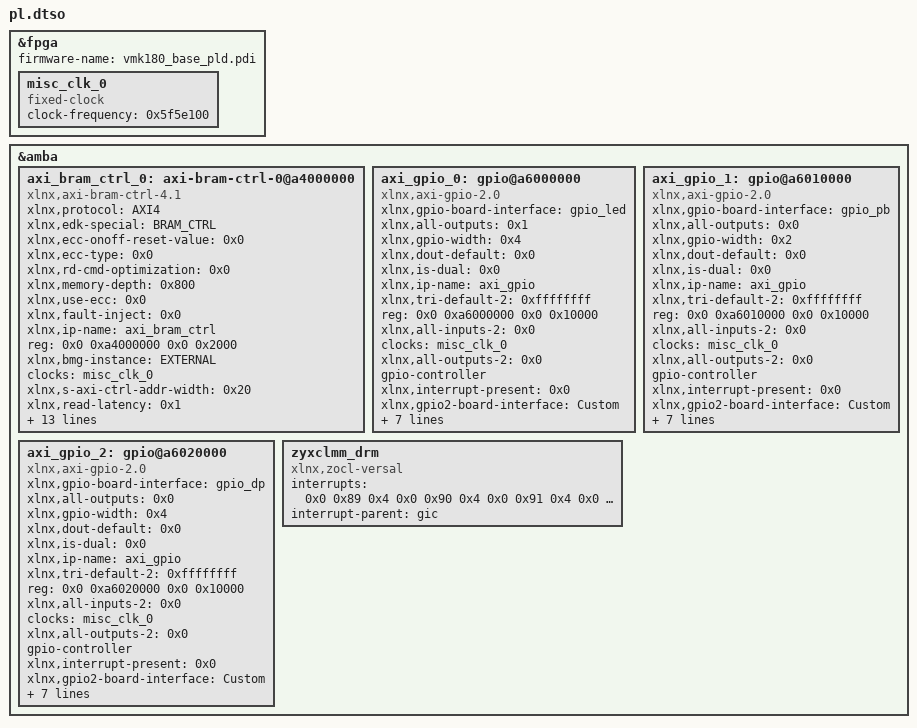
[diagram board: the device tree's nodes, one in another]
/dts-v1/;
/plugin/;

&fpga {
        firmware-name = "vmk180_base_pld.pdi";

        misc_clk_0: misc_clk_0 {
                compatible = "fixed-clock";
                clock-frequency = <0x5f5e100>;
                #clock-cells = <0x0>;
        };
};

&amba {

        axi_bram_ctrl_0: axi-bram-ctrl-0@a4000000 {
                xlnx,protocol = "AXI4";
                xlnx,edk-special = "BRAM_CTRL";
                compatible = "xlnx,axi-bram-ctrl-4.1", "xlnx,axi-bram-ctrl";
                xlnx,ecc-onoff-reset-value = <0x0>;
                xlnx,ecc-type = <0x0>;
                xlnx,rd-cmd-optimization = <0x0>;
                xlnx,memory-depth = <0x800>;
                xlnx,use-ecc = <0x0>;
                xlnx,fault-inject = <0x0>;
                xlnx,ip-name = "axi_bram_ctrl";
                reg = <0x0 0xa4000000 0x0 0x2000>;
                xlnx,bmg-instance = "EXTERNAL";
                clocks = <&misc_clk_0>;
                xlnx,s-axi-ctrl-addr-width = <0x20>;
                xlnx,read-latency = <0x1>;
                xlnx,id-width = <0x0>;
                xlnx,s-axi-supports-narrow-burst = <0x0>;
                xlnx,supports-narrow-burst = <0x0>;
                xlnx,single-port-bram = <0x0>;
                xlnx,ecc = <0x0>;
                xlnx,edk-iptype = "PERIPHERAL";
                clock-names = "s_axi_aclk";
                xlnx,data-width = <0x20>;
                xlnx,bram-addr-width = <0xb>;
                xlnx,bram-inst-mode = "EXTERNAL";
                xlnx,s-axi-ctrl-data-width = <0x20>;
                xlnx,mem-depth = <0x800>;
                xlnx,s-axi-id-width = <0x1>;
                xlnx,name = "axi_bram_ctrl_0";
        };

        axi_gpio_0: gpio@a6000000 {
                xlnx,gpio-board-interface = "gpio_led";
                compatible = "xlnx,axi-gpio-2.0", "xlnx,xps-gpio-1.00.a";
                xlnx,all-outputs = <0x1>;
                #gpio-cells = <0x2>;
                xlnx,gpio-width = <0x4>;
                xlnx,dout-default = <0x0>;
                xlnx,is-dual = <0x0>;
                xlnx,ip-name = "axi_gpio";
                xlnx,tri-default-2 = <0xffffffff>;
                reg = <0x0 0xa6000000 0x0 0x10000>;
                xlnx,all-inputs-2 = <0x0>;
                clocks = <&misc_clk_0>;
                xlnx,all-outputs-2 = <0x0>;
                gpio-controller;
                device_type = "gpio";
                xlnx,interrupt-present = <0x0>;
                xlnx,gpio2-board-interface = "Custom";
                xlnx,edk-iptype = "PERIPHERAL";
                xlnx,dout-default-2 = <0x0>;
                xlnx,gpio2-width = <0x20>;
                clock-names = "s_axi_aclk";
                xlnx,use-board-flow;
                xlnx,tri-default = <0xffffffff>;
                xlnx,name = "axi_gpio_0";
                xlnx,all-inputs = <0x0>;
        };

        axi_gpio_1: gpio@a6010000 {
                xlnx,gpio-board-interface = "gpio_pb";
                compatible = "xlnx,axi-gpio-2.0", "xlnx,xps-gpio-1.00.a";
                xlnx,all-outputs = <0x0>;
                #gpio-cells = <0x2>;
                xlnx,gpio-width = <0x2>;
                xlnx,dout-default = <0x0>;
                xlnx,is-dual = <0x0>;
                xlnx,ip-name = "axi_gpio";
                xlnx,tri-default-2 = <0xffffffff>;
                reg = <0x0 0xa6010000 0x0 0x10000>;
                xlnx,all-inputs-2 = <0x0>;
                clocks = <&misc_clk_0>;
                xlnx,all-outputs-2 = <0x0>;
                gpio-controller;
                device_type = "gpio";
                xlnx,interrupt-present = <0x0>;
                xlnx,gpio2-board-interface = "Custom";
                xlnx,edk-iptype = "PERIPHERAL";
                xlnx,dout-default-2 = <0x0>;
                xlnx,gpio2-width = <0x20>;
                clock-names = "s_axi_aclk";
                xlnx,use-board-flow;
                xlnx,tri-default = <0xffffffff>;
                xlnx,name = "axi_gpio_1";
                xlnx,all-inputs = <0x1>;
        };

        axi_gpio_2: gpio@a6020000 {
                xlnx,gpio-board-interface = "gpio_dp";
                compatible = "xlnx,axi-gpio-2.0", "xlnx,xps-gpio-1.00.a";
                xlnx,all-outputs = <0x0>;
                #gpio-cells = <0x2>;
                xlnx,gpio-width = <0x4>;
                xlnx,dout-default = <0x0>;
                xlnx,is-dual = <0x0>;
                xlnx,ip-name = "axi_gpio";
                xlnx,tri-default-2 = <0xffffffff>;
                reg = <0x0 0xa6020000 0x0 0x10000>;
                xlnx,all-inputs-2 = <0x0>;
                clocks = <&misc_clk_0>;
                xlnx,all-outputs-2 = <0x0>;
                gpio-controller;
                device_type = "gpio";
                xlnx,interrupt-present = <0x0>;
                xlnx,gpio2-board-interface = "Custom";
                xlnx,edk-iptype = "PERIPHERAL";
                xlnx,dout-default-2 = <0x0>;
                xlnx,gpio2-width = <0x20>;
                clock-names = "s_axi_aclk";
                xlnx,use-board-flow;
                xlnx,tri-default = <0xffffffff>;
                xlnx,name = "axi_gpio_2";
                xlnx,all-inputs = <0x1>;
        };

        zyxclmm_drm {
                interrupts = <0x0 0x89 0x4 0x0 0x90 0x4 0x0 0x91 0x4 0x0 0x92 0x4 0x0 0x93 0x4 0x0 0x94 0x4 0x0 0x95 0x4 0x0 0x96 0x4>;
                interrupt-parent = <&gic>;
                compatible = "xlnx,zocl-versal";
        };
};

